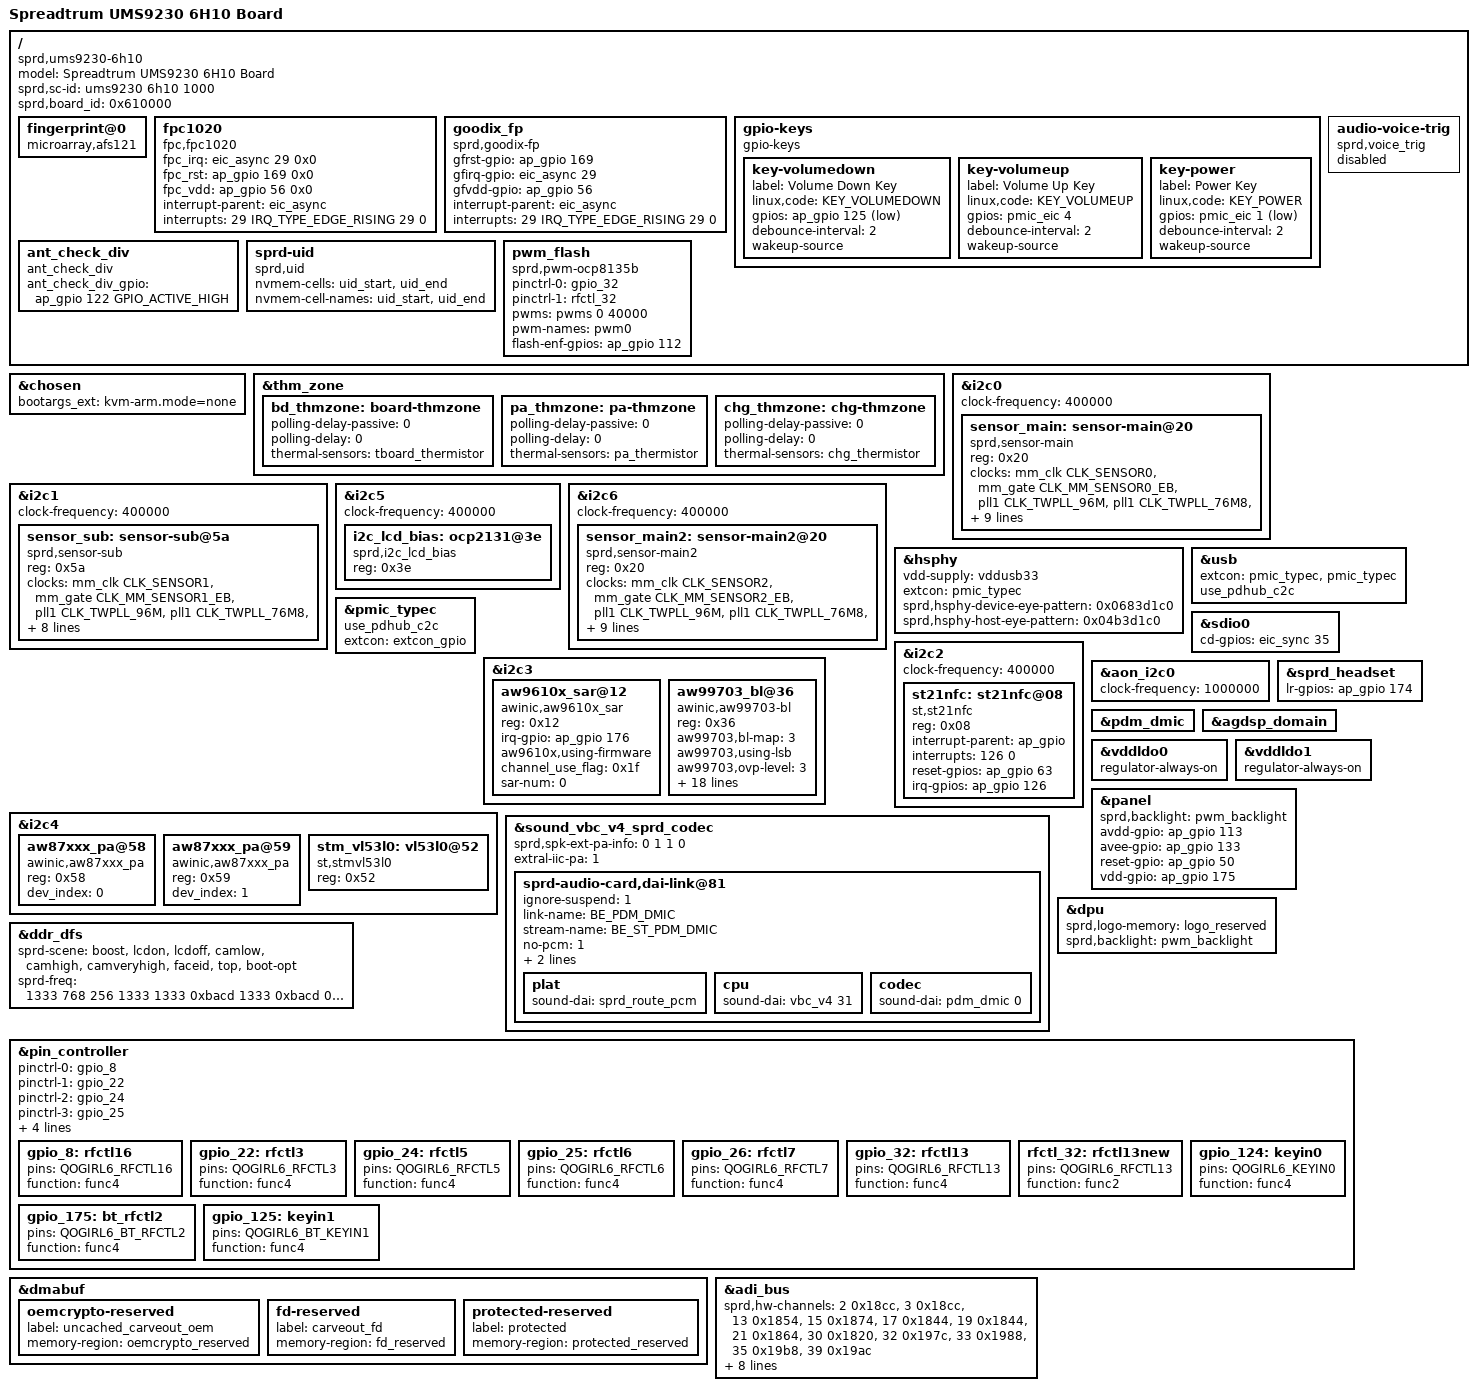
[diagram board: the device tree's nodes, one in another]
// SPDX-License-Identifier: GPL-2.0-only
/*
 * Spreadtrum Qogirl6 board common DTS file
 *
 * Copyright (C) 2021, Unisoc Inc.
 */

/dts-v1/;
/plugin/;
#include "lcd/lcd_nt36672c_tm_mipi_fhd.dtsi"
#include "lcd/lcd_ft8726_csot_mipi_fhd.dtsi"
#include "lcd/lcd_ili7807s_txd_mipi_fhd.dtsi"
#include "lcd/lcd_nt36672c2_tm_mipi_fhd.dtsi"
#include <dt-bindings/input/input.h>
#include <dt-bindings/gpio/gpio.h>
#include <dt-bindings/interrupt-controller/arm-gic.h>
#include <dt-bindings/clock/sprd,ums9230-clk.h>
#include <dt-bindings/mfd/sprd,sc2730-regs.h>
#include <dt-bindings/mfd/sprd,sc2730-mask.h>
#include <dt-bindings/usb/pd.h>
#include "lcd/lcd_g40396_truly_mipi_fhd.dtsi"
#include "lcd/lcd_nt36672e_truly_mipi_fhd_nodsc.dtsi"
//#include "lcd/lcd_nt36672e_truly_mipi_fhd.dtsi"
#include "lcd/lcd_dummy_mipi.dtsi"
#include "touchscreen/ums9230-spi3-gpio144-145-tp.dtsi"
#include "battery/cancun-overlay.dtsi"
#include "reserved-memory/cancun-overlay.dtsi"
#include "ums9230/wcn.dtsi"
#include "wcn/wcn_modules.h"
#include "wcn/chip/wcn-integrate-sharkl6-register.dtsi"

/ {

	model = "Spreadtrum UMS9230 6H10 Board";

	compatible = "sprd,ums9230-6h10";

	sprd,sc-id = "ums9230 6h10 1000";

	sprd,board_id = <0x610000>; //XXYY00:base board,XXYY00~XXYYFF:customize board

	fragment {
		target-path = "/";
		__overlay__ {
			/*pwm_backlight: sprd_backlight {
				compatible = "sprd,sharkl6-backlight";
				pwms = <&pwms 2 40000>;
				pwm-names = "backlight";
				sprd,max-brightness-level = <924>;
				default-brightness-level = <262>;
				sprd,brightness-scale = <1023>;
				brightness-levels = <
							  0   3   4   5   6   7
					  8   9  10  11  12  13  14  16  17  18
					 19  20  21  22  23  24  25  26  27  28
					 29  31  33  35  37  39  41  43  45  47
					 48  50  52  54  56  58  60  62  64  67
					 69  72  74  76  78  80  82  84  86  88
					 90  92  94  96  98 100 102 104 107 109
					112 114 116 118 120 122 124 126 128 130
					132 134 136 138 140 142 144 147 149 151
					154 156 158 160 162 164 166 168 170 172
					175 178 181 184 187 190 193 196 199 203
					205 208 211 214 217 220 223 226 229 234
					237 240 243 247 250 253 256 259 263 266
					269 270 274 277 280 283 287 290 294 297
					300 303 307 310 314 318 325 329 334 339
					340 343 347 350 354 358 365 369 374 380
					382 385 389 392 396 400 407 411 416 422
					426 430 434 438 442 446 452 457 460 464
					470 474 480 486 492 498 504 508 512 516
					522 527 532 536 540 545 550 555 561 568
					574 579 584 589 594 600 605 610 615 620
					625 630 635 641 647 652 657 662 667 673
					688 694 700 706 712 716 720 725 730 735
					740 746 752 758 764 770 776 782 790 798
					803 810 817 825 832 840 845 850 855 861
					866 872 878 884 890 896 903 911 918 924
				>;
			};*/

			fingerprint@0 {
				compatible = "microarray,afs121";
				//fpint-gpios = <&eic_async 29 0>;
			};

			fpc1020 {
				status = "ok";
				compatible = "fpc,fpc1020";
				fpc_irq = <&eic_async 29 0x0>;
				fpc_rst = <&ap_gpio 169 0x0>;
				fpc_vdd = <&ap_gpio 56 0x0>;
				interrupt-parent = <&eic_async>;
				interrupts = <29 IRQ_TYPE_EDGE_RISING 29 0>;
				/* vfp-supply = <&pm8994_l18>; */ // use regulator power
			};

			goodix_fp {
				compatible = "sprd,goodix-fp";
				gfrst-gpio = <&ap_gpio 169 0x00>;
				gfirq-gpio = <&eic_async 29 0x00>;
				gfvdd-gpio = <&ap_gpio 56 0x0>;
				interrupt-parent = <&eic_async>;
				interrupts = <29 IRQ_TYPE_EDGE_RISING 29 0>;
				status = "okay";
			};

			gpio-keys {
				compatible = "gpio-keys";

				key-volumedown {
					label = "Volume Down Key";
					linux,code = <KEY_VOLUMEDOWN>;
					gpios = <&ap_gpio 125 GPIO_ACTIVE_LOW>;
					debounce-interval = <2>;
					wakeup-source;
				};

				key-volumeup {
					label = "Volume Up Key";
					linux,code = <KEY_VOLUMEUP>;
					gpios = <&pmic_eic 4 GPIO_ACTIVE_HIGH>;
					debounce-interval = <2>;
					wakeup-source;
				};

				key-power {
					label = "Power Key";
					linux,code = <KEY_POWER>;
					gpios = <&pmic_eic 1 GPIO_ACTIVE_LOW>;
					debounce-interval = <2>;
					wakeup-source;
				};
			};
			ant_check_div {
				compatible = "ant_check_div";
				ant_check_div_gpio = <&ap_gpio 122 GPIO_ACTIVE_HIGH>;
			};

			audio-voice-trig {
				status = "disable";
				compatible = "sprd,voice_trig";
				//irq_gpio = <&ap_gpio 169 GPIO_ACTIVE_HIGH>;
			};

			sprd-uid {
				compatible = "sprd,uid";
				nvmem-cells = <&uid_start>, <&uid_end>;
				nvmem-cell-names = "uid_start", "uid_end";
			};
                        pwm_flash: pwm_flash {
                                compatible = "sprd,pwm-ocp8135b";
                                pinctrl-names = "gpio_32","rfctl_32";
                                pinctrl-0 = <&gpio_32>;
                                pinctrl-1 = <&rfctl_32>;
                                pwms = <&pwms 0 40000>;
                                pwm-names = "pwm0";
                                flash-enf-gpios = <&ap_gpio 112 0>;
                                #pwm-cells = <2>;
                        };

		};
	};
};

&chosen {
	bootargs_ext = "kvm-arm.mode=none";
};

&thm_zone {
	bd_thmzone: board-thmzone {
		polling-delay-passive = <0>;
		polling-delay = <0>;
		thermal-sensors = <&tboard_thermistor>;
	};

	pa_thmzone: pa-thmzone {
		polling-delay-passive = <0>;
		polling-delay = <0>;
		thermal-sensors = <&pa_thermistor>;
	};

	chg_thmzone: chg-thmzone {
		polling-delay-passive = <0>;
		polling-delay = <0>;
		thermal-sensors = <&chg_thermistor>;
	};
};

&i2c0 {
	status = "okay";
	clock-frequency = <400000>;
	#address-cells = <1>;
	#size-cells = <0>;

	sensor_main: sensor-main@20 {
		compatible = "sprd,sensor-main";
		reg = <0x20>;
		clock-names = "clk_src","sensor_eb",
			"clk_96m","clk_76m8",
			"clk_48m","clk_26m";
		clocks = <&mm_clk CLK_SENSOR0>,<&mm_gate CLK_MM_SENSOR0_EB>,
				<&pll1 CLK_TWPLL_96M>,<&pll1 CLK_TWPLL_76M8>,
				<&pll1 CLK_TWPLL_48M>,<&ext_26m>;
		vddio-supply = <&vddcamio>;
		avdd-gpios = <&ap_gpio 47 0>;
		dvdd-gpios = <&ap_gpio 174 0>;
		vddcammot-supply = <&vddcammot>;
		reset-gpios = <&ap_gpio 44 0>;
		//power-down-gpios = <&ap_gpio 47 0>;
		sprd,phyid = <2>;
		csi = <&csi0>;
		power-domains = <&mm_domain>;
	};
};

&i2c1 {
	status = "okay";
	clock-frequency = <400000>;
	#address-cells = <1>;
	#size-cells = <0>;

    sensor_sub: sensor-sub@5a {
        compatible = "sprd,sensor-sub";
        reg = <0x5a>;
        clock-names = "clk_src","sensor_eb",
            "clk_96m","clk_76m8",
            "clk_48m","clk_26m";
        clocks = <&mm_clk CLK_SENSOR1>,<&mm_gate CLK_MM_SENSOR1_EB>,
                 <&pll1 CLK_TWPLL_96M>,<&pll1 CLK_TWPLL_76M8>,
                 <&pll1 CLK_TWPLL_48M>,<&ext_26m>;
        vddio-supply = <&vddcamio>;
        vddcama-supply = <&vddcama1>;
        vddcamd-supply = <&vddcamd1>;
    /*  avdd-gpios = <&ap_gpio 33 0>;*/
    /*  mot-gpios = <&ap_gpio 88 0>;*/
        reset-gpios = <&ap_gpio 45 0>;
    /*  power-down-gpios = <&ap_gpio 40 0>;*/
    /*  mipi-switch-en-gpios = <&ap_gpio 55 0>;*/
    /*  mipi-switch-mode-gpios = <&ap_gpio 8 0>;*/
        sprd,phyid = <0>;
        csi = <&csi1>;
        power-domains = <&mm_domain>;
	};


};

&i2c5 {
	status = "okay";
	clock-frequency = <400000>;

	i2c_lcd_bias: ocp2131@3e {
		compatible = "sprd,i2c_lcd_bias";
		reg = <0x3e>;
		status = "okay";
	};
};

&i2c6 {
	status = "okay";
	clock-frequency = <400000>;
	#address-cells = <1>;
	#size-cells = <0>;

    sensor_main2: sensor-main2@20 {
        compatible = "sprd,sensor-main2";
        reg = <0x20>;
        clock-names = "clk_src","sensor_eb",
            "clk_96m","clk_76m8",
            "clk_48m","clk_26m";
        clocks = <&mm_clk CLK_SENSOR2>,<&mm_gate CLK_MM_SENSOR2_EB>,
                 <&pll1 CLK_TWPLL_96M>,<&pll1 CLK_TWPLL_76M8>,
                 <&pll1 CLK_TWPLL_48M>,<&ext_26m>;
        vddio-supply = <&vddcamio>;
        vddcama-supply = <&vddcama0>;
        vddcamd-supply = <&vddcamd0>;
        reset-gpios = <&ap_gpio 41 0>;
        avdd-gpios = <&ap_gpio 137 0>;
        sprd,phyid = <3>;
        csi = <&csi1>;
        power-domains = <&mm_domain>;
    };
};

&hsphy {
	vdd-supply = <&vddusb33>;
	extcon = <&pmic_typec>;
	sprd,hsphy-device-eye-pattern = <0x0683d1c0>;
	sprd,hsphy-host-eye-pattern = <0x04b3d1c0>;
	status = "okay";
};

&usb {
	extcon = <&pmic_typec>, <&pmic_typec>;
	//vbus-supply = <&vddvbus>;
	//vbus1-supply = <&vddvbus1>;
	status = "okay";
	use_pdhub_c2c;
};

&pmic_typec {
	use_pdhub_c2c;
	extcon = <&extcon_gpio>;
	status = "okay";
};

&sdio0 {
	cd-gpios = <&eic_sync 35 GPIO_ACTIVE_HIGH>;
};


&i2c2{
    status = "okay";
    clock-frequency = <400000>;
    #address-cells = <1>;
    #size-cells = <0>;
    st21nfc: st21nfc@08 {
        compatible = "st,st21nfc";
        reg = <0x08>;
        interrupt-parent = <&ap_gpio>;
        interrupts = <126  0>;
        reset-gpios = <&ap_gpio 63 0x00>;
        irq-gpios = <&ap_gpio 126 0x00>;
        // pidle-gpios = <&ap_gpio 48 0x00>;
        //clkreq-gpios = <&ap_gpio 60 0x00>;
        //clocks = <&clock_rpmh RPMH_RF_CLK3>;
        clock-names = "nfc_ref_clk","source","enable";
        //st,clk_pinctrl;
        //i2c-retry = <0>;
        status = "okay";
    };

};


&i2c3 {
	status = "okay";
	#address-cells = <1>;
	#size-cells = <0>;
	aw9610x_sar@12 {
                 compatible = "awinic,aw9610x_sar";
                 reg = <0x12>;
                 //reset-gpio = <&ap_gpio 63 0>;
                 irq-gpio = <&ap_gpio 176 0>;
                 aw9610x,using-firmware;
                 //vcc0-supply = <&pm660l_l4>;
                 channel_use_flag = <0x1f>;
                 sar-num = <0>;
                 status = "okay";
         };
	aw99703_bl@36 {
		compatible = "awinic,aw99703-bl";
		reg = <0x36>;
		/* brightness map level 1:256,2:1024,3:2048 */
		aw99703,bl-map = <3>;
		aw99703,using-lsb;
		aw99703,ovp-level = <3>;
		aw99703,ocp-level = <2>;
		aw99703,switch-freq = <1>;
		aw99703,hwen-gpio = <&ap_gpio 129 GPIO_ACTIVE_HIGH>;
		aw99703,auto-freq-high = <0x80>;
		aw99703,auto-freq-low = <0x10>;
		aw99703,bl-fscal-led = <0x1A>; /*0x1A=25.6mA 0x19=24.8mA 0x13=20mA*/
		aw99703,bl-channel = <3>;
		aw99703,turn-on-ramp = <0x05>;
		aw99703,turn-off-ramp = <0x05>;
		aw99703,pwm-trans-dim = <0>;
		aw99703,i2c-trans-dim = <0>;
		aw99703,pwm-mode = <0>;
		aw99703,map-type = <1>;
		aw99703,work-mode = <1>;
		aw99703,flash-timeout-time = <0x05>;
		aw99703,flash-current = <0x08>;
		aw99703,efuse-config = <0x1C 0x61 0x61 0x4C 0x2C 0xC0 0x08 0x00 0x01 0xC0 0x00 0x00 0x50>;
	};
};

&i2c4 {
	status = "okay";
	#address-cells = <1>;
	#size-cells = <0>;

		/* AWINIC AW87XXX PA */
	aw87xxx_pa@58 {
		compatible = "awinic,aw87xxx_pa";
		reg = <0x58>;
		dev_index = < 0 >;
		status = "okay";
	};

	aw87xxx_pa@59 {
		compatible = "awinic,aw87xxx_pa";
		reg = <0x59>;
		dev_index = < 1 >;
		status = "okay";
	};
	
	stm_vl53l0: vl53l0@52 {
		compatible = "st,stmvl53l0";
		reg = <0x52>;
		//reset_gpios = <168>;
		//irq_gpios = <169>;
		//interrupt-parent = <&ap_gpio>;
		//interrupts = <169 IRQ_TYPE_LEVEL_LOW>;
	};
};

&aon_i2c0 {
	status = "okay";
	clock-frequency = <1000000>;
};

&sprd_headset {
	status = "okay";
	lr-gpios = <&ap_gpio 174 GPIO_ACTIVE_HIGH>;
};

&pdm_dmic {
	status = "okay";
};

&agdsp_domain {
	status = "okay";
};

&sound_vbc_v4_sprd_codec {
	status = "okay";
	sprd,spk-ext-pa-info = <0 1 1 0>;
	extral-iic-pa = <1>;


	/*
	 * node 54 and node 55 (index 36 and 37) are reserved for
	 * "ucp1301-spk2" and "ucp1301-rcv"
	 * nodes from 56 to 67 (index from 38 to 49) are used by HIFI
	 */

	/* 63: pdm dmic */
	sprd-audio-card,dai-link@81 {
		ignore-suspend = <1>;
		link-name = "BE_PDM_DMIC";
		stream-name = "BE_ST_PDM_DMIC";
		no-pcm = <1>;
		dpcm-capture = <1>;
		be-id = <0>;
		//dai-format = "i2s";
		plat {
			sound-dai = <&sprd_route_pcm>;
		};
		cpu {
			sound-dai = <&vbc_v4 31>;
		};
		codec {
			sound-dai = <&pdm_dmic 0>;
		};
	};
};

&vddldo0 {
	regulator-always-on;
};

&vddldo1 {
	regulator-always-on;
};

&panel {
	sprd,backlight = <&pwm_backlight>;
	avdd-gpio = <&ap_gpio 113 GPIO_ACTIVE_HIGH>;
	avee-gpio = <&ap_gpio 133 GPIO_ACTIVE_HIGH>;
	reset-gpio = <&ap_gpio 50 GPIO_ACTIVE_HIGH>;
	vdd-gpio = <&ap_gpio 175 GPIO_ACTIVE_HIGH>;
};

&dpu {
	sprd,logo-memory = <&logo_reserved>;

	sprd,backlight = <&pwm_backlight>;
};

&ddr_dfs {
	  sprd-scene = "boost", "lcdon", "lcdoff", "camlow",
			"camhigh", "camveryhigh", "faceid", "top", "boot-opt";
	  sprd-freq = <1333 768 256 1333 1333 0xbacd 1333 0xbacd 0xbacd>;
};

&pin_controller {
	pinctrl-names =
	/* rfctl16 ,rfctl3, rfctl5 */
	"gpio_8", "gpio_22", "gpio_24",
	/* rfctl6, rfctl7, keyin0 */
	"gpio_25", "gpio_26", "gpio_32", "rfctl_32", "gpio_124",
	/* bt_rfctl2 */
	"gpio_175";
	pinctrl-0 = <&gpio_8>;
	pinctrl-1 = <&gpio_22>;
	pinctrl-2 = <&gpio_24>;
	pinctrl-3 = <&gpio_25>;
	pinctrl-4 = <&gpio_26>;
	pinctrl-5 = <&gpio_124>;
	pinctrl-6 = <&gpio_175>;
	pinctrl-7 = <&gpio_125>;

	gpio_8: rfctl16 {
		pins = "QOGIRL6_RFCTL16";
		function = "func4";
	};

	gpio_22: rfctl3 {
		pins = "QOGIRL6_RFCTL3";
		function = "func4";
	};

	gpio_24: rfctl5 {
		pins = "QOGIRL6_RFCTL5";
		function = "func4";
	};

	gpio_25: rfctl6 {
		pins = "QOGIRL6_RFCTL6";
		function = "func4";
	};

	gpio_26: rfctl7 {
		pins = "QOGIRL6_RFCTL7";
		function = "func4";
	};
        gpio_32: rfctl13 {
		pins = "QOGIRL6_RFCTL13";
		function = "func4";
	};

        rfctl_32: rfctl13new {
		pins = "QOGIRL6_RFCTL13";
		function = "func2";
	};

	gpio_124: keyin0 {
		pins = "QOGIRL6_KEYIN0";
		function = "func4";
	};

	gpio_175: bt_rfctl2 {
		pins = "QOGIRL6_BT_RFCTL2";
		function = "func4";
	};

	gpio_125: keyin1 {
		pins = "QOGIRL6_BT_KEYIN1";
		function = "func4";
	};
};

&dmabuf {
	oemcrypto-reserved {
		label = "uncached_carveout_oem";
		memory-region = <&oemcrypto_reserved>;
	};

	fd-reserved {
		label = "carveout_fd";
		memory-region = <&fd_reserved>;
	};


	protected-reserved {
		label = "protected";
		memory-region = <&protected_reserved>;
	};
};

&adi_bus {
	sprd,hw-channels = <2 0x18cc>, <3 0x18cc>, <13 0x1854>, <15 0x1874>,
			<17 0x1844>, <19 0x1844>, <21 0x1864>, <30 0x1820>,
			<32 0x197c>, <33 0x1988>, <35 0x19b8>, <39 0x19ac>;
	sprd,hw-channels0 = <2 0x18cc>, <3 0x18cc>, <13 0x1874>, <15 0x1874>,
			<17 0x1844>, <19 0x1854>, <21 0x1864>, <30 0x1820>,
			<32 0x197c>, <33 0x1988>, <35 0x19b8>, <39 0x19ac>;
	sprd,hw-channels1 = <2 0x18cc>, <3 0x18cc>, <13 0x1854>, <15 0x1874>,
			<17 0x1844>, <19 0x1844>, <21 0x1864>, <30 0x1820>,
			<32 0x197c>, <33 0x1988>, <35 0x19b8>, <39 0x19ac>;
};
